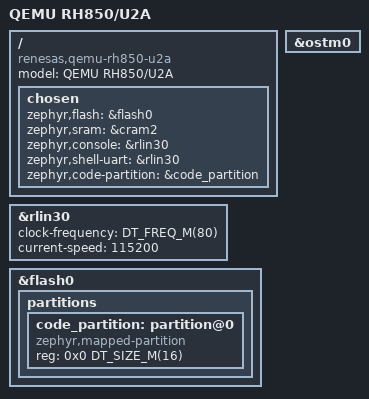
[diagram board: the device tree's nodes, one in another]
/*
 * SPDX-FileCopyrightText: Copyright (c) 2026 Linumiz
 *
 * SPDX-License-Identifier: Apache-2.0
 */

/dts-v1/;

#include <freq.h>
#include <renesas/r7f702300.dtsi>

/ {
	compatible = "renesas,qemu-rh850-u2a";
	model = "QEMU RH850/U2A";

	chosen {
		zephyr,flash = &flash0;
		zephyr,sram = &cram2;
		zephyr,console = &rlin30;
		zephyr,shell-uart = &rlin30;
		zephyr,code-partition = &code_partition;
	};
};

/* CLK_RLIN3 = CLK_HSB, 80 MHz */
&rlin30 {
	clock-frequency = <DT_FREQ_M(80)>;
	current-speed = <115200>;
	status = "okay";
};

&ostm0 {
	status = "okay";
};

&flash0 {
	partitions {
		ranges;
		#address-cells = <1>;
		#size-cells = <1>;

		code_partition: partition@0 {
			compatible = "zephyr,mapped-partition";
			reg = <0x0 DT_SIZE_M(16)>;
		};
	};
};
